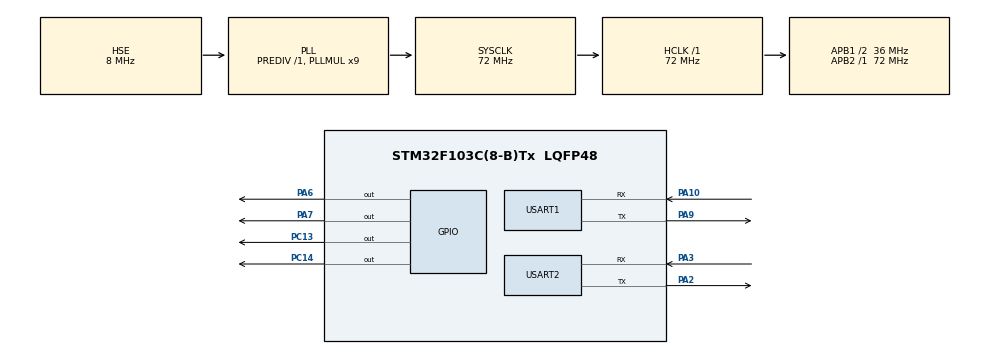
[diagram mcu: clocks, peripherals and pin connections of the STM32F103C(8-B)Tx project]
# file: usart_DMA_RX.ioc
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Dma.Request0=USART1_RX
Dma.Request1=USART2_RX
Dma.USART1_RX.0.Direction=DMA_PERIPH_TO_MEMORY
Dma.USART1_RX.0.Instance=DMA1_Channel5
Dma.USART1_RX.0.MemDataAlignment=DMA_MDATAALIGN_BYTE
Dma.USART1_RX.0.MemInc=DMA_MINC_ENABLE
Dma.USART1_RX.0.Mode=DMA_NORMAL
Dma.USART1_RX.0.PeriphDataAlignment=DMA_PDATAALIGN_BYTE
Dma.USART1_RX.0.PeriphInc=DMA_PINC_DISABLE
Dma.USART1_RX.0.Priority=DMA_PRIORITY_LOW
Dma.USART2_RX.1.Direction=DMA_PERIPH_TO_MEMORY
Dma.USART2_RX.1.Instance=DMA1_Channel6
Dma.USART2_RX.1.MemDataAlignment=DMA_MDATAALIGN_BYTE
Dma.USART2_RX.1.MemInc=DMA_MINC_ENABLE
Dma.USART2_RX.1.Mode=DMA_NORMAL
Dma.USART2_RX.1.PeriphDataAlignment=DMA_PDATAALIGN_BYTE
Dma.USART2_RX.1.PeriphInc=DMA_PINC_DISABLE
Dma.USART2_RX.1.Priority=DMA_PRIORITY_LOW
IWDG.Prescaler=IWDG_PRESCALER_64
IWDG.Reload=2500
Mcu.Family=STM32F1
Mcu.Name=STM32F103C(8-B)Tx
Mcu.Package=LQFP48
NVIC.DMA1_Channel5_IRQn=true\:0\:0\:false\:false\:true
NVIC.DMA1_Channel6_IRQn=true\:0\:0\:false\:false\:true
NVIC.PriorityGroup=NVIC_PRIORITYGROUP_4
NVIC.TIM3_IRQn=true\:2\:0\:true\:false\:true
NVIC.TIM4_IRQn=true\:2\:0\:true\:false\:true
NVIC.USART1_IRQn=true\:1\:0\:true\:false\:true
NVIC.USART2_IRQn=true\:1\:0\:true\:false\:true
PA10.Mode=Asynchronous
PA10.Signal=USART1_RX
PA13.Mode=Serial_Wire
PA13.Signal=SYS_JTMS-SWDIO
PA14.Mode=Serial_Wire
PA14.Signal=SYS_JTCK-SWCLK
PA2.Mode=Asynchronous
PA2.Signal=USART2_TX
PA3.Mode=Asynchronous
PA3.Signal=USART2_RX
PA6.Signal=GPIO_Output
PA7.Signal=GPIO_Output
PA9.Mode=Asynchronous
PA9.Signal=USART1_TX
PC13-TAMPER-RTC.Signal=GPIO_Output
PC14-OSC32_IN.Signal=GPIO_Output
PD0-OSC_IN.Mode=HSE-External-Oscillator
PD0-OSC_IN.Signal=RCC_OSC_IN
PD1-OSC_OUT.Mode=HSE-External-Oscillator
PD1-OSC_OUT.Signal=RCC_OSC_OUT
ProjectManager.HeapSize=0x200
ProjectManager.StackSize=0x400
ProjectManager.TargetToolchain=MDK-ARM V5
RCC.AHBFreq_Value=72000000
RCC.APB1CLKDivider=RCC_HCLK_DIV2
RCC.APB1Freq_Value=36000000
RCC.APB1TimFreq_Value=72000000
RCC.APB2Freq_Value=72000000
RCC.APB2TimFreq_Value=72000000
RCC.HCLKFreq_Value=72000000
RCC.PLLMUL=RCC_PLL_MUL9
RCC.PLLSourceVirtual=RCC_PLLSOURCE_HSE
RCC.SYSCLKFreq_VALUE=72000000
RCC.SYSCLKSource=RCC_SYSCLKSOURCE_PLLCLK
RCC.USBFreq_Value=72000000
TIM3.Period=99
TIM3.Prescaler=719
TIM4.Period=19999
TIM4.Prescaler=7199
USART1.VirtualMode=VM_ASYNC
USART2.VirtualMode=VM_ASYNC
VP_IWDG_VS_IWDG.Mode=IWDG_Activate
VP_TIM3_VS_ClockSourceINT.Mode=Internal
VP_TIM4_VS_ClockSourceINT.Mode=Internal
board=usart_DMA_RX

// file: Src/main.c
/**
  ******************************************************************************
  * File Name          : main.c
  * Description        : Main program body
  ******************************************************************************
  ** This notice applies to any and all portions of this file
  * that are not between comment pairs USER CODE BEGIN and
  * USER CODE END. Other portions of this file, whether
  * inserted by the user or by software development tools
  * are owned by their respective copyright owners.
  *
  * COPYRIGHT(c) 2019 STMicroelectronics
  *
  * Redistribution and use in source and binary forms, with or without modification,
  * are permitted provided that the following conditions are met:
  *   1. Redistributions of source code must retain the above copyright notice,
  *      this list of conditions and the following disclaimer.
  *   2. Redistributions in binary form must reproduce the above copyright notice,
  *      this list of conditions and the following disclaimer in the documentation
  *      and/or other materials provided with the distribution.
  *   3. Neither the name of STMicroelectronics nor the names of its contributors
  *      may be used to endorse or promote products derived from this software
  *      without specific prior written permission.
  *
  * THIS SOFTWARE IS PROVIDED BY THE COPYRIGHT HOLDERS AND CONTRIBUTORS "AS IS"
  * AND ANY EXPRESS OR IMPLIED WARRANTIES, INCLUDING, BUT NOT LIMITED TO, THE
  * IMPLIED WARRANTIES OF MERCHANTABILITY AND FITNESS FOR A PARTICULAR PURPOSE ARE
  * DISCLAIMED. IN NO EVENT SHALL THE COPYRIGHT HOLDER OR CONTRIBUTORS BE LIABLE
  * FOR ANY DIRECT, INDIRECT, INCIDENTAL, SPECIAL, EXEMPLARY, OR CONSEQUENTIAL
  * DAMAGES (INCLUDING, BUT NOT LIMITED TO, PROCUREMENT OF SUBSTITUTE GOODS OR
  * SERVICES; LOSS OF USE, DATA, OR PROFITS; OR BUSINESS INTERRUPTION) HOWEVER
  * CAUSED AND ON ANY THEORY OF LIABILITY, WHETHER IN CONTRACT, STRICT LIABILITY,
  * OR TORT (INCLUDING NEGLIGENCE OR OTHERWISE) ARISING IN ANY WAY OUT OF THE USE
  * OF THIS SOFTWARE, EVEN IF ADVISED OF THE POSSIBILITY OF SUCH DAMAGE.
  *
  ******************************************************************************
  */
#include "main.h"
#include "stm32f1xx_hal.h"

/* USER CODE BEGIN Includes */
#include "include.h"
/* USER CODE END Includes */

IWDG_HandleTypeDef hiwdg;

TIM_HandleTypeDef htim3;
TIM_HandleTypeDef htim4;

UART_HandleTypeDef huart1;
UART_HandleTypeDef huart2;
DMA_HandleTypeDef hdma_usart1_rx;
DMA_HandleTypeDef hdma_usart2_rx;

/* USER CODE BEGIN PV */
/* Private variables ---------------------------------------------------------*/

/* USER CODE END PV */

void SystemClock_Config(void);
static void MX_GPIO_Init(void);
static void MX_DMA_Init(void);
static void MX_USART1_UART_Init(void);
static void MX_USART2_UART_Init(void);
static void MX_TIM3_Init(void);
static void MX_TIM4_Init(void);
static void MX_IWDG_Init(void);

/* USER CODE BEGIN PFP */
/* Private function prototypes -----------------------------------------------*/

/* USER CODE END PFP */

int main(void)
{

    /* MCU Configuration----------------------------------------------------------*/

    /* Reset of all peripherals, Initializes the Flash interface and the Systick. */
    HAL_Init();

    /* Configure the system clock */
    SystemClock_Config();

    /* Initialize all configured peripherals */
    delay_init(72);

    MX_GPIO_Init();
    MX_DMA_Init();
    MX_USART1_UART_Init();
    MX_USART2_UART_Init();
    MX_TIM3_Init();
    MX_TIM4_Init();
    //MX_IWDG_Init();

    /* USER CODE BEGIN 2 */
    HAL_TIM_Base_Start_IT(&htim3);
    HAL_TIM_Base_Start_IT(&htim4);

    __HAL_UART_ENABLE_IT(&huart2, UART_IT_IDLE);//串口2空闲中断
    HAL_UART_Receive_DMA(&huart2, Usart_data, 256);//使能串口2DMA接收
    __HAL_UART_ENABLE_IT(&huart1, UART_IT_IDLE);//串口1空闲中断
    HAL_UART_Receive_DMA(&huart1, modbus.rcbuf, 256);//使能串口2DMA接收 -》
    Param_Init();
    /* USER CODE END 2 */

    /* Infinite loop */
    while(1)
    {

        Mosbus_Event();
        LCD_Data_Del();
        time_control_handle();
    }

}

/** System Clock Configuration
*/
void SystemClock_Config(void)
{

    RCC_OscInitTypeDef RCC_OscInitStruct;
    RCC_ClkInitTypeDef RCC_ClkInitStruct;

    /**Initializes the CPU, AHB and APB busses clocks
    */
    RCC_OscInitStruct.OscillatorType = RCC_OSCILLATORTYPE_LSI | RCC_OSCILLATORTYPE_HSE;
    RCC_OscInitStruct.HSEState = RCC_HSE_ON;
    RCC_OscInitStruct.HSEPredivValue = RCC_HSE_PREDIV_DIV1;
    RCC_OscInitStruct.HSIState = RCC_HSI_ON;
    RCC_OscInitStruct.LSIState = RCC_LSI_ON;
    RCC_OscInitStruct.PLL.PLLState = RCC_PLL_ON;
    RCC_OscInitStruct.PLL.PLLSource = RCC_PLLSOURCE_HSE;
    RCC_OscInitStruct.PLL.PLLMUL = RCC_PLL_MUL9;
    if(HAL_RCC_OscConfig(&RCC_OscInitStruct) != HAL_OK)
    {
        _Error_Handler(__FILE__, __LINE__);
    }

    /**Initializes the CPU, AHB and APB busses clocks
    */
    RCC_ClkInitStruct.ClockType = RCC_CLOCKTYPE_HCLK | RCC_CLOCKTYPE_SYSCLK
                                  | RCC_CLOCKTYPE_PCLK1 | RCC_CLOCKTYPE_PCLK2;
    RCC_ClkInitStruct.SYSCLKSource = RCC_SYSCLKSOURCE_PLLCLK;
    RCC_ClkInitStruct.AHBCLKDivider = RCC_SYSCLK_DIV1;
    RCC_ClkInitStruct.APB1CLKDivider = RCC_HCLK_DIV2;
    RCC_ClkInitStruct.APB2CLKDivider = RCC_HCLK_DIV1;

    if(HAL_RCC_ClockConfig(&RCC_ClkInitStruct, FLASH_LATENCY_2) != HAL_OK)
    {
        _Error_Handler(__FILE__, __LINE__);
    }

    /**Configure the Systick interrupt time
    */
    HAL_SYSTICK_Config(HAL_RCC_GetHCLKFreq() / 1000);

    /**Configure the Systick
    */
    HAL_SYSTICK_CLKSourceConfig(SYSTICK_CLKSOURCE_HCLK);

    /* SysTick_IRQn interrupt configuration */
    HAL_NVIC_SetPriority(SysTick_IRQn, 0, 0);
}

/* IWDG init function */
static void MX_IWDG_Init(void)
{

    hiwdg.Instance = IWDG;
    hiwdg.Init.Prescaler = IWDG_PRESCALER_64;
    hiwdg.Init.Reload = 2500;
    if(HAL_IWDG_Init(&hiwdg) != HAL_OK)
    {
        _Error_Handler(__FILE__, __LINE__);
    }

}

/* TIM3 init function */
static void MX_TIM3_Init(void)
{

    TIM_ClockConfigTypeDef sClockSourceConfig;
    TIM_MasterConfigTypeDef sMasterConfig;

    htim3.Instance = TIM3;
    htim3.Init.Prescaler = 719;
    htim3.Init.CounterMode = TIM_COUNTERMODE_UP;
    htim3.Init.Period = 99;
    htim3.Init.ClockDivision = TIM_CLOCKDIVISION_DIV1;
    if(HAL_TIM_Base_Init(&htim3) != HAL_OK)
    {
        _Error_Handler(__FILE__, __LINE__);
    }

    sClockSourceConfig.ClockSource = TIM_CLOCKSOURCE_INTERNAL;
    if(HAL_TIM_ConfigClockSource(&htim3, &sClockSourceConfig) != HAL_OK)
    {
        _Error_Handler(__FILE__, __LINE__);
    }

    sMasterConfig.MasterOutputTrigger = TIM_TRGO_RESET;
    sMasterConfig.MasterSlaveMode = TIM_MASTERSLAVEMODE_DISABLE;
    if(HAL_TIMEx_MasterConfigSynchronization(&htim3, &sMasterConfig) != HAL_OK)
    {
        _Error_Handler(__FILE__, __LINE__);
    }

}

/* TIM4 init function */
static void MX_TIM4_Init(void)
{

    TIM_ClockConfigTypeDef sClockSourceConfig;
    TIM_MasterConfigTypeDef sMasterConfig;

    htim4.Instance = TIM4;
    htim4.Init.Prescaler = 7199;
    htim4.Init.CounterMode = TIM_COUNTERMODE_UP;
    htim4.Init.Period = 19999;
    htim4.Init.ClockDivision = TIM_CLOCKDIVISION_DIV1;
    if(HAL_TIM_Base_Init(&htim4) != HAL_OK)
    {
        _Error_Handler(__FILE__, __LINE__);
    }

    sClockSourceConfig.ClockSource = TIM_CLOCKSOURCE_INTERNAL;
    if(HAL_TIM_ConfigClockSource(&htim4, &sClockSourceConfig) != HAL_OK)
    {
        _Error_Handler(__FILE__, __LINE__);
    }

    sMasterConfig.MasterOutputTrigger = TIM_TRGO_RESET;
    sMasterConfig.MasterSlaveMode = TIM_MASTERSLAVEMODE_DISABLE;
    if(HAL_TIMEx_MasterConfigSynchronization(&htim4, &sMasterConfig) != HAL_OK)
    {
        _Error_Handler(__FILE__, __LINE__);
    }

}

/* USART1 init function */
static void MX_USART1_UART_Init(void)
{

    huart1.Instance = USART1;
    huart1.Init.BaudRate = 9600;
    huart1.Init.WordLength = UART_WORDLENGTH_8B;
    huart1.Init.StopBits = UART_STOPBITS_1;
    huart1.Init.Parity = UART_PARITY_NONE;
    huart1.Init.Mode = UART_MODE_TX_RX;
    huart1.Init.HwFlowCtl = UART_HWCONTROL_NONE;
    huart1.Init.OverSampling = UART_OVERSAMPLING_16;
    if(HAL_UART_Init(&huart1) != HAL_OK)
    {
        _Error_Handler(__FILE__, __LINE__);
    }

}

/* USART2 init function */
static void MX_USART2_UART_Init(void)
{

    huart2.Instance = USART2;
    huart2.Init.BaudRate = 115200;
    huart2.Init.WordLength = UART_WORDLENGTH_8B;
    huart2.Init.StopBits = UART_STOPBITS_1;
    huart2.Init.Parity = UART_PARITY_NONE;
    huart2.Init.Mode = UART_MODE_TX_RX;
    huart2.Init.HwFlowCtl = UART_HWCONTROL_NONE;
    huart2.Init.OverSampling = UART_OVERSAMPLING_16;
    if(HAL_UART_Init(&huart2) != HAL_OK)
    {
        _Error_Handler(__FILE__, __LINE__);
    }

}

static void MX_DMA_Init(void)
{
    /* DMA controller clock enable */
    __HAL_RCC_DMA1_CLK_ENABLE();

    /* DMA interrupt init */
    /* DMA1_Channel5_IRQn interrupt configuration */
    HAL_NVIC_SetPriority(DMA1_Channel5_IRQn, 0, 0);
    HAL_NVIC_EnableIRQ(DMA1_Channel5_IRQn);
    /* DMA1_Channel6_IRQn interrupt configuration */
    HAL_NVIC_SetPriority(DMA1_Channel6_IRQn, 0, 0);
    HAL_NVIC_EnableIRQ(DMA1_Channel6_IRQn);

}

/** Configure pins as
        * Analog
        * Input
        * Output
        * EVENT_OUT
        * EXTI
*/
static void MX_GPIO_Init(void)
{

    GPIO_InitTypeDef GPIO_InitStruct;

    /* GPIO Ports Clock Enable */
    __HAL_RCC_GPIOC_CLK_ENABLE();
    __HAL_RCC_GPIOD_CLK_ENABLE();
    __HAL_RCC_GPIOA_CLK_ENABLE();

    /*Configure GPIO pin Output Level */
    HAL_GPIO_WritePin(GPIOC, GPIO_PIN_13 | GPIO_PIN_14, GPIO_PIN_RESET);

    /*Configure GPIO pin Output Level */
    HAL_GPIO_WritePin(GPIOA, GPIO_PIN_6 | GPIO_PIN_7, GPIO_PIN_RESET);

    /*Configure GPIO pins : PC13 PC14 */
    GPIO_InitStruct.Pin = GPIO_PIN_13 | GPIO_PIN_14;
    GPIO_InitStruct.Mode = GPIO_MODE_OUTPUT_PP;
    GPIO_InitStruct.Speed = GPIO_SPEED_FREQ_LOW;
    HAL_GPIO_Init(GPIOC, &GPIO_InitStruct);

    /*Configure GPIO pins : PA6 PA7 */
    GPIO_InitStruct.Pin = GPIO_PIN_6 | GPIO_PIN_7;
    GPIO_InitStruct.Mode = GPIO_MODE_OUTPUT_PP;
    GPIO_InitStruct.Speed = GPIO_SPEED_FREQ_LOW;
    HAL_GPIO_Init(GPIOA, &GPIO_InitStruct);

}

void _Error_Handler(char* file, int line)
{
    while(1)
    {
    }
}

/************************ (C) COPYRIGHT STMicroelectronics *****END OF FILE****/
